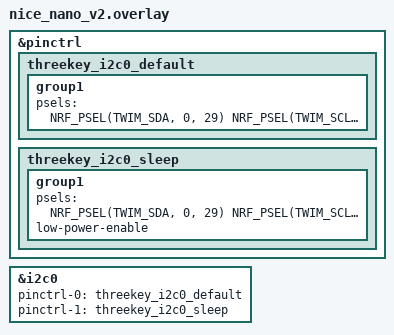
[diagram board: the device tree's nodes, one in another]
/*
 * Override nice_nano_v2 I2C pins
 *
 * Default:
 * SDA = P0.17
 * SCL = P0.20
 *
 * New:
 * SDA = P0.29
 * SCL = P0.31
 */


&pinctrl {

    threekey_i2c0_default: threekey_i2c0_default {

        group1 {

            psels = <
                NRF_PSEL(TWIM_SDA, 0, 29)
                NRF_PSEL(TWIM_SCL, 0, 31)
            >;

        };

    };


    threekey_i2c0_sleep: threekey_i2c0_sleep {

        group1 {

            psels = <
                NRF_PSEL(TWIM_SDA, 0, 29)
                NRF_PSEL(TWIM_SCL, 0, 31)
            >;

            low-power-enable;

        };

    };

};


&i2c0 {

    pinctrl-0 = <&threekey_i2c0_default>;

    pinctrl-1 = <&threekey_i2c0_sleep>;

    pinctrl-names =
        "default",
        "sleep";

    status = "okay";

};
